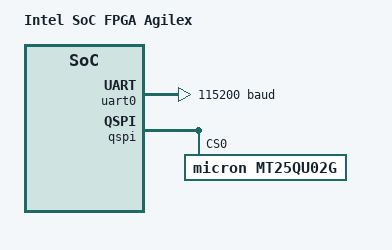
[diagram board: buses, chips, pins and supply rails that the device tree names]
/*
 * Copyright (c) 2021-2023, Intel Corporation.
 *
 * SPDX-License-Identifier: Apache-2.0
 */


/dts-v1/;

#include <intel/intel_socfpga_agilex.dtsi>

/ {
	model = "Intel SoC FPGA Agilex";
	compatible = "intel,socfpga-agilex";
	#address-cells = <1>;
	#size-cells = <1>;

	chosen {
		zephyr,console = &uart0;
		zephyr,shell-uart = &uart0;
		zephyr,sram = &mem0;
	};
	psci {
		compatible = "arm,psci-0.2";
		method = "smc";
	};
};

&uart0 {
	status = "okay";
	current-speed = <115200>;
};

&qspi {
	mt25qu02g@0 {
		compatible = "micron,mt25qu02g";
		reg = <0>;
		size = <DT_SIZE_M(256*8)>; /* in bits */
		status = "okay";
	};
};
